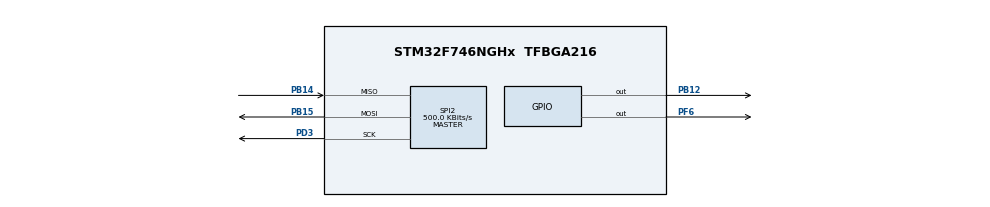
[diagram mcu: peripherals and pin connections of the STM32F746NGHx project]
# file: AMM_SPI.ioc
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Mcu.Family=STM32F7
Mcu.Name=STM32F746NGHx
Mcu.Package=TFBGA216
NVIC.PriorityGroup=NVIC_PRIORITYGROUP_4
PB12.GPIO_Speed=GPIO_SPEED_FREQ_VERY_HIGH
PB12.Signal=GPIO_Output
PB14.Mode=Full_Duplex_Master
PB14.Signal=SPI2_MISO
PB15.Mode=Full_Duplex_Master
PB15.Signal=SPI2_MOSI
PD3.Mode=Full_Duplex_Master
PD3.Signal=SPI2_SCK
PE4.Signal=SPI4_NSS
PF6.Signal=GPIO_Output
ProjectManager.HeapSize=0x200
ProjectManager.StackSize=0x400
ProjectManager.TargetToolchain=STM32CubeIDE
RCC.AHBCLKDivider=RCC_SYSCLK_DIV2
RCC.AHBFreq_Value=8000000
RCC.APB1Freq_Value=8000000
RCC.APB1TimFreq_Value=8000000
RCC.APB2Freq_Value=8000000
RCC.APB2TimFreq_Value=8000000
RCC.CortexFreq_Value=8000000
RCC.HCLKFreq_Value=8000000
RCC.HSE_VALUE=25000000
RCC.HSI_VALUE=16000000
RCC.LSE_VALUE=32768
RCC.USBFreq_Value=96000000
RCC.VCOOutputFreq_Value=192000000
SPI2.BaudRatePrescaler=SPI_BAUDRATEPRESCALER_16
SPI2.CalculateBaudRate=500.0 KBits/s
SPI2.DataSize=SPI_DATASIZE_8BIT
SPI2.Direction=SPI_DIRECTION_2LINES
SPI2.Mode=SPI_MODE_MASTER
SPI2.VirtualType=VM_MASTER
board=custom

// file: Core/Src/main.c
/* USER CODE BEGIN Header */
/**
  ******************************************************************************
  * @file           : main.c
  * @brief          : Main program body
  ******************************************************************************
  * @attention
  *
  * Copyright (c) 2023 STMicroelectronics.
  * All rights reserved.
  *
  * This software is licensed under terms that can be found in the LICENSE file
  * in the root directory of this software component.
  * If no LICENSE file comes with this software, it is provided AS-IS.
  *
  ******************************************************************************
  */
/* USER CODE END Header */
#include "main.h"

/* USER CODE BEGIN Includes */
#include  "AD7779.h"
/* USER CODE END Includes */

SPI_HandleTypeDef hspi2;

void SystemClock_Config(void);
static void MX_GPIO_Init(void);
static void MX_SPI2_Init(void);

int main(void)
{

  /* MCU Configuration--------------------------------------------------------*/

  /* Reset of all peripherals, Initializes the Flash interface and the Systick. */
  HAL_Init();

  /* Configure the system clock */
  SystemClock_Config();

  /* Initialize all configured peripherals */
  MX_GPIO_Init();
  MX_SPI2_Init();

  /* Infinite loop */
  while (1)
  {

  }
}

void SystemClock_Config(void)
{
  RCC_OscInitTypeDef RCC_OscInitStruct = {0};
  RCC_ClkInitTypeDef RCC_ClkInitStruct = {0};

  /** Configure the main internal regulator output voltage
  */
  __HAL_RCC_PWR_CLK_ENABLE();
  __HAL_PWR_VOLTAGESCALING_CONFIG(PWR_REGULATOR_VOLTAGE_SCALE3);

  /** Initializes the RCC Oscillators according to the specified parameters
  * in the RCC_OscInitTypeDef structure.
  */
  RCC_OscInitStruct.OscillatorType = RCC_OSCILLATORTYPE_HSI;
  RCC_OscInitStruct.HSIState = RCC_HSI_ON;
  RCC_OscInitStruct.HSICalibrationValue = RCC_HSICALIBRATION_DEFAULT;
  RCC_OscInitStruct.PLL.PLLState = RCC_PLL_NONE;
  if (HAL_RCC_OscConfig(&RCC_OscInitStruct) != HAL_OK)
  {
    Error_Handler();
  }

  /** Initializes the CPU, AHB and APB buses clocks
  */
  RCC_ClkInitStruct.ClockType = RCC_CLOCKTYPE_HCLK|RCC_CLOCKTYPE_SYSCLK
                              |RCC_CLOCKTYPE_PCLK1|RCC_CLOCKTYPE_PCLK2;
  RCC_ClkInitStruct.SYSCLKSource = RCC_SYSCLKSOURCE_HSI;
  RCC_ClkInitStruct.AHBCLKDivider = RCC_SYSCLK_DIV2;
  RCC_ClkInitStruct.APB1CLKDivider = RCC_HCLK_DIV1;
  RCC_ClkInitStruct.APB2CLKDivider = RCC_HCLK_DIV1;

  if (HAL_RCC_ClockConfig(&RCC_ClkInitStruct, FLASH_LATENCY_0) != HAL_OK)
  {
    Error_Handler();
  }
}

static void MX_SPI2_Init(void)
{

  /* SPI2 parameter configuration*/
  hspi2.Instance = SPI2;
  hspi2.Init.Mode = SPI_MODE_MASTER;
  hspi2.Init.Direction = SPI_DIRECTION_2LINES;
  hspi2.Init.DataSize = SPI_DATASIZE_8BIT;
  hspi2.Init.CLKPolarity = SPI_POLARITY_LOW;
  hspi2.Init.CLKPhase = SPI_PHASE_1EDGE;
  hspi2.Init.NSS = SPI_NSS_SOFT;
  hspi2.Init.BaudRatePrescaler = SPI_BAUDRATEPRESCALER_16;
  hspi2.Init.FirstBit = SPI_FIRSTBIT_MSB;
  hspi2.Init.TIMode = SPI_TIMODE_DISABLE;
  hspi2.Init.CRCCalculation = SPI_CRCCALCULATION_DISABLE;
  hspi2.Init.CRCPolynomial = 7;
  hspi2.Init.CRCLength = SPI_CRC_LENGTH_DATASIZE;
  hspi2.Init.NSSPMode = SPI_NSS_PULSE_ENABLE;
  if (HAL_SPI_Init(&hspi2) != HAL_OK)
  {
    Error_Handler();
  }

}

static void MX_GPIO_Init(void)
{
  GPIO_InitTypeDef GPIO_InitStruct = {0};

  /* GPIO Ports Clock Enable */
  __HAL_RCC_GPIOE_CLK_ENABLE();
  __HAL_RCC_GPIOD_CLK_ENABLE();
  __HAL_RCC_GPIOF_CLK_ENABLE();
  __HAL_RCC_GPIOB_CLK_ENABLE();

  /*Configure GPIO pin Output Level */
  HAL_GPIO_WritePin(GPIOF, GPIO_PIN_6, GPIO_PIN_RESET);

  /*Configure GPIO pin Output Level */
  HAL_GPIO_WritePin(GPIOB, GPIO_PIN_12, GPIO_PIN_RESET);

  /*Configure GPIO pin : PE4 */
  GPIO_InitStruct.Pin = GPIO_PIN_4;
  GPIO_InitStruct.Mode = GPIO_MODE_AF_PP;
  GPIO_InitStruct.Pull = GPIO_NOPULL;
  GPIO_InitStruct.Speed = GPIO_SPEED_FREQ_VERY_HIGH;
  GPIO_InitStruct.Alternate = GPIO_AF5_SPI4;
  HAL_GPIO_Init(GPIOE, &GPIO_InitStruct);

  /*Configure GPIO pin : PF6 */
  GPIO_InitStruct.Pin = GPIO_PIN_6;
  GPIO_InitStruct.Mode = GPIO_MODE_OUTPUT_PP;
  GPIO_InitStruct.Pull = GPIO_NOPULL;
  GPIO_InitStruct.Speed = GPIO_SPEED_FREQ_LOW;
  HAL_GPIO_Init(GPIOF, &GPIO_InitStruct);

  /*Configure GPIO pin : PB12 */
  GPIO_InitStruct.Pin = GPIO_PIN_12;
  GPIO_InitStruct.Mode = GPIO_MODE_OUTPUT_PP;
  GPIO_InitStruct.Pull = GPIO_NOPULL;
  GPIO_InitStruct.Speed = GPIO_SPEED_FREQ_VERY_HIGH;
  HAL_GPIO_Init(GPIOB, &GPIO_InitStruct);

}

void Error_Handler(void)
{
  __disable_irq();
  while (1)
  {
  }
}
